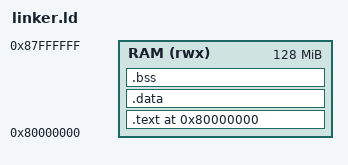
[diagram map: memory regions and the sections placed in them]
ENTRY(_start)

MEMORY
{
  RAM (rwx) : ORIGIN = 0x80000000, LENGTH = 128M
}

PHDRS
{
  text PT_LOAD FLAGS(5);
  data PT_LOAD FLAGS(6);
}

SECTIONS
{
  . = ORIGIN(RAM);

  .text : ALIGN(4)
  {
    KEEP(*(.init))
    *(.text .text.*)
    *(.rodata .rodata.*)
  } > RAM :text

  .data : ALIGN(8)
  {
    __data_start = .;
    *(.data .data.*)
    __data_end = .;
  } > RAM :data

  .bss (NOLOAD) : ALIGN(8)
  {
    __bss_start = .;
    *(.bss .bss.*)
    *(COMMON)
    . = ALIGN(8);
    __bss_end = .;
  } > RAM :data

  . = ALIGN(16);
  __stack_top = ORIGIN(RAM) + LENGTH(RAM);
}
